# CC1312PSIP register map
File version: 1.0
CPU: CM4 1.0, other endian, MPU, FPU, 3 interrupt priority bits
Registers are 32-bit, read-write, reset 0x0 unless marked. A register's access mark holds for its fields unless they carry their own. Offsets are from the block's base; [hi:lo] are bit positions; {n}, {i} and the like mark numbered series; 'fields as' and 'values as' point back to an identical list.

## AON_IOC — Always On (AON) IO Controller - controls IO operation when the MCU IO Controller (IOC) is powered off and resides in the AON domain. Note: This module only supports 32 bit Read/Write access from MCU.
Base 0x40094000
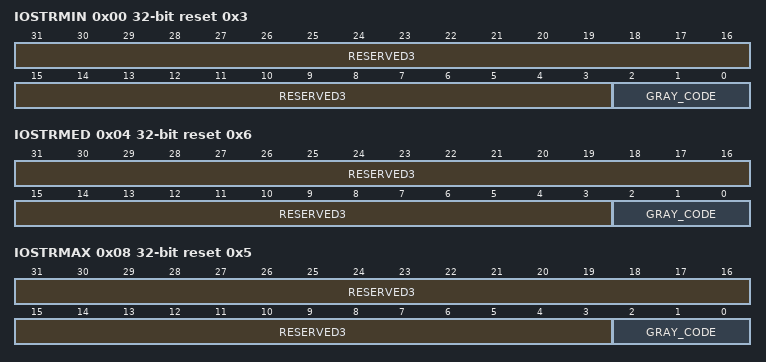
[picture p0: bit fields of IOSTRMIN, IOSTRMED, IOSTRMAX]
0x00 IOSTRMIN reset 0x3 — Internal. Only to be used through TI provided API.
  [31:3] RESERVED3 ro — [31:3] Internal. Only to be used through TI provided API.
  [2:0] GRAY_CODE — [2:0] Internal. Only to be used through TI provided API.
0x04 IOSTRMED reset 0x6 — Internal. Only to be used through TI provided API.
  fields as IOSTRMIN
0x08 IOSTRMAX reset 0x5 — Internal. Only to be used through TI provided API.
  fields as IOSTRMIN
0x10 CLK32KCTL reset 0x1 — SCLK_LF External Output Control
  [0] OE_N — [0:0] 0: Output enable active. SCLK_LF output on IO pin that has PORT_ID (for example IOC:IOCFG0.PORT_ID) set to AON_CLK32K. 1: Output enable not active
0x14 TCKCTL reset 0x1 — TCK IO Pin Control
  [0] EN — [0:0] 0: Input driver for TCK disabled. 1: Input driver for TCK enabled.

## AUX_SMPH — AUX Semaphore (AUX_SMPH) provides hardware means to share modules in AUX safely between CPUs based on resource ownership. AUX_SMPH operates at AUX bus rate.
Base 0x400C8000
{0x0+4i} SMPH{i} reset 0x1 (i=0..7) — Semaphore {i}
  [0] STAT — [0:0] Request or release of semaphore. Request by read: 0: Semaphore not available. 1: Semaphore granted. Release by write: 0: Do not use. 1: Release semaphore.
0x20 AUTOTAKE — Auto Take Sticky Request for Single Semaphore.
  [2:0] SMPH_ID — [2:0] Write the semaphore ID,0x0-0x7, to SMPH_ID to request this semaphore until it is granted. When semaphore SMPH_ID is granted, event AUX_EVCTL:EVSTAT3.AUX_SMPH_AUTOTAKE_DONE becomes 1. The event becomes 0 when software releases the semaphore or writes a new value to SMPH_ID. To avoid corrupted semaphores: - Usage of this functionality must be restricted to one CPU core. - Software must wait until AUX_EVCTL:EVSTAT3.AUX_SMPH_AUTOTAKE_DONE is 1 before it writes a new value to SMPH_ID.

## AUX_SPIM — The AUX Serial Peripheral Interface Master (AUX_SPIM) enables AUX_SCE with power-efficient SPI communication. It is not possible to write a register while SPI transmission occurs. An attempt to do so will stall the bus until transmission is complete. Read of RX8.DATA or RX16.DATA stalls the bus until LSB has been captured. Read of SCLKIDLE.STAT or DATAIDLE.STAT stalls the bus until condition described is met. Other read operations do not stall the bus. AUX_SCE becomes clock gated if it encounters a bus stall. This is useful as AUX_SCE can write TX8.DATA and then read RX8.DATA immediately to read a SPI slave. In such case there is no need for software to wait or to poll registers. AUX_SYSIF:PEROPRATE.SPIM_OP_RATE selects the peripheral clock frequency which is used to derive the SCLK frequency. AUX_SCE must set AUX_SYSIF:PEROPRATE.SPIM_OP_RATE to SCE_RATE to access and use AUX_SPIM. System CPU must set AUX_SYSIF:PEROPRATE.SPIM_OP_RATE to BUS_RATE to access and use AUX_SPIM. Failure to do so can result in incorrect SPI transmission.
Base 0x400C1000
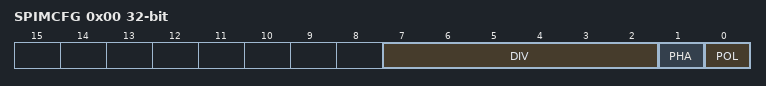
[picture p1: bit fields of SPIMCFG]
0x00 SPIMCFG — SPI Master Configuration Write operation stalls until current transfer completes.
  [7:2] DIV — [7:2] SCLK divider. Peripheral clock frequency division gives the SCLK clock frequency. The division factor equals (2 * (DIV+1)): 0x00: Divide by 2. 0x01: Divide by 4. 0x02: Divide by 6. ... 0x3F: Divide by 128.
  [1] PHA — [1:1] Phase of the MOSI and MISO data signals. 0: Sample MISO at leading (odd) edges and shift MOSI at trailing (even) edges of SCLK. 1: Sample MISO at trailing (even) edges and shift MOSI at leading (odd) edges of SCLK.
  [0] POL — [0:0] Polarity of the SCLK signal. 0: SCLK is low when idle, first clock edge rises. 1: SCLK is high when idle, first clock edge falls.
0x04 MISOCFG — MISO Configuration Write operation stalls until current transfer completes.
  [4:0] AUXIO — [4:0] AUXIO to MISO mux. Select the AUXIO pin that connects to MISO.
0x08 MOSICTL — MOSI Control Write operation stalls until current transfer completes.
  [0] VALUE wo — [0:0] MOSI level control. 0: Set MOSI low. 1: Set MOSI high.
0x0C TX8 — Transmit 8 Bit Write operation stalls until current transfer completes.
  [7:0] DATA wo — [7:0] 8 bit data transfer. Write DATA to start transfer, MSB first. When transfer completes, MOSI stays at the value of LSB.
0x10 TX16 — Transmit 16 Bit Write operation stalls until current transfer completes.
  [15:0] DATA wo — [15:0] 16 bit data transfer. Write DATA to start transfer, MSB first. When transfer completes, MOSI stays at the value of LSB.
0x14 RX8 — Receive 8 Bit Read operation stalls until current transfer completes.
  [7:0] DATA ro — [7:0] Latest 8 bits received on MISO.
0x18 RX16 — Receive 16 Bit Read operation stalls until current transfer completes.
  [15:0] DATA ro — [15:0] Latest 16 bits received on MISO.
0x1C SCLKIDLE reset 0x1 — SCLK Idle Read operation stalls until SCLK is idle with no remaining clock edges.
  [0] STAT ro — [0:0] Wait for SCLK idle. Read operation stalls until SCLK is idle with no remaining clock edges. Read then returns 1. AUX_SCE can use this to control CS deassertion.
0x20 DATAIDLE reset 0x1 — Data Idle Read operation stalls until current transfer completes.
  [0] STAT ro — [0:0] Wait for data idle. Read operation stalls until the SCLK period associated with LSB transmission completes. Read then returns 1. AUX_SCE can use this to control CS deassertion.
